# tviibh16m register map
Vendor: Infineon Technologies; Series: TVIIBH16M; File version: 1.0
CPU: CM7 r0p1, little endian, MPU, FPU, double-precision FPU, I-cache, D-cache, VTOR, ITCM, DTCM, 3 interrupt priority bits, 16 interrupts
Registers are 32-bit, read-write, reset 0x0 unless marked. A register's access mark holds for its fields unless they carry their own. Offsets are from the block's base; [hi:lo] are bit positions; {n}, {i} and the like mark numbered series; 'fields as' and 'values as' point back to an identical list.

## FLEXRAY0 (part 2 of 3) — FlexRay Bus Interface
Base 0x40560000
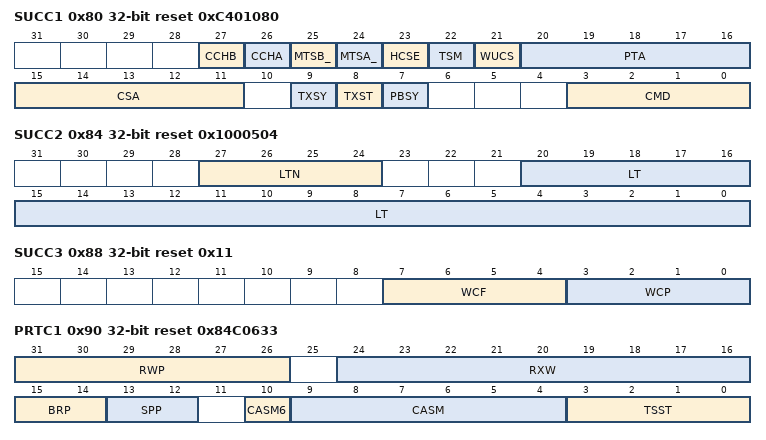
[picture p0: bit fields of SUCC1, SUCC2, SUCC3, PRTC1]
0x80 SUCC1 reset 0xC401080 — SUC Configuration Register 1
  [27] CCHB — Connected to Channel B (pChannels) Configures whether the node is connected to channel B. 1 = Node connected to channel B (default after hard reset) 0 = Not connected to channel B
    0=CH_B_NOT_CONNECTED (N/A); 1=CH_B_CONNECTED (N/A)
  [26] CCHA — Connected to Channel A (pChannels) Configures whether the node is connected to channel A. 1 = Node connected to channel A (default after hard reset) 0 = Not connected to channel A
    0=CH_A_NOT_CONNECTED (N/A); 1=CH_A_CONNECTED (N/A)
  [25] MTSB_ — Select Channel B for MTS Transmission The bit selects channel B for MTS symbol transmission. The flag is reset by default and may be modified only in DEFAULT_CONFIG or CONFIG state. 1 = Channel B selected for MTS transmission 0 = Channel B disabled for MTS transmission
    0=CH_B_DISABLED_FOR_MTS_TXMN (N/A); 1=CH_B_SELECTED_FOR_MTS_TXMN (N/A)
  [24] MTSA_ — Select Channel A for MTS Transmission The bit selects channel A for MTS symbol transmission. The flag is reset by default and may be modified only in DEFAULT_CONFIG or CONFIG state. 1 = Channel A selected for MTS transmission 0 = Channel A disabled for MTS transmission
    0=CH_A_DISABLED_FOR_MTS_TXMN (N/A); 1=CH_A_SELECTED_FOR_MTS_TXMN (N/A)
  [23] HCSE — Halt due to Clock Sync Error (pAllowHaltDueToClock) Controls the transition to HALT state due to a clock synchronization error. The bit can be modified in DEFAULT_CONFIG or CONFIG state only. 1 = CC will enter HALT state 0 = CC will enter / remain in NORMAL_PASSIVE
    0=CC_TO_ENTER_NORMAL_PASSIVE (N/A); 1=CC_TO_ENTER_HALT (N/A)
  [22] TSM — Transmission Slot Mode (pSingleSlotEnabled) Selects the initial transmission slot mode. In SINGLE slot mode the CC may only transmit in the preconfigured key slot. The key slot ID is configured in the header section of message buffer 0 respectively message buffers 0 and 1 depending on bit MRC.SPLM. In case TSM = '1', message buffer 0 respectively message buffers 0,1 can be (re)configured in DEFAULT_CONFIG or CONFIG state only. In ALL slot mode the CC may transmit in all slots. TSM is a configuration bit which can only be set / reset by the Host. The bit can be written in DEFAULT_CONFIG or CONFIG state only. The CC changes to ALL slot mode when the Host successfully applied the ALL_SLOTS command by writing CMD[3:0] = '0101' in POC states NORMAL_ACTIVE or NORMAL_PASSIVE. The actual slot mode is monitored by CCSV.SLM[1:0]. 1 = SINGLE Slot Mode (default after hard reset) 0 = ALL Slot Mode
    0=ALL_SLOT_MODE (N/A); 1=SINGLE_SLOT_MODE (N/A)
  [21] WUCS — Wakeup Channel Select (pWakeupChannel) With this bit the Host selects the channel on which the CC sends the Wakeup pattern. The CC ignores any attempt to change the status of this bit when not in DEFAULT_CONFIG or CONFIG state. 1 = Send wakeup pattern on channel B 0 = Send wakeup pattern on channel A
    0=SEND_WKUP_PATTERN_ON_CH_A (N/A); 1=SEND_WKUP_PATTERN_ON_CH_B (N/A)
  [20:16] PTA — Passive to Active (pAllowPassiveToActive) Defines the number of consecutive even / odd cycle pairs that must have valid clock correction terms before the CC is allowed to transit from NORMAL_PASSIVE to NORMAL_ACTIVE state. If set to '00000' the CC is not allowed to transit from NORMAL_PASSIVE to NORMAL_ACTIVE state. It can be modified in DEFAULT_CONFIG or CONFIG state only. Valid values are 0 to 31 even / odd cycle pairs.
  [15:11] CSA — Cold Start Attempts (gColdStartAttempts) Configures the maximum number of attempts that a cold starting node is permitted to try to start up the network without receiving any valid response from another node. It can be modified in DEFAULT_CONFIG or CONFIG state only. Must be identical in all nodes of a cluster. Valid values are 2 to 31.
    2=MIN (N/A)
  [9] TXSY — Transmit Sync Frame in Key Slot (pKeySlotUsedForSync) Defines whether the key slot is used to transmit sync frames. The bit can be modified in DEFAULT_CONFIG or CONFIG state only. 1 = Key slot used to transmit sync frame, node is sync node 0 = No sync frame transmission in key slot, node is neither sync nor coldstart node
    0=NO_SYNC_FRAME_TXMN (N/A); 1=SYNC_FRAME_TXMN (N/A)
  [8] TXST — Transmit Startup Frame in Key Slot (pKeySlotUsedForStartup) Defines whether the key slot is used to transmit startup frames. The bit can be modified in DEFAULT_CONFIG or CONFIG state only. 1 = Key slot used to transmit startup frame, node is leading or following coldstarter 0 = No startup frame transmission in key slot, node is non-coldstarter
    0=NO_STARTUP_FRAME_TXMN (N/A); 1=STARTUP_FRAME_TXMN (N/A)
  [7] PBSY ro — POC Busy Signals that the POC is busy and cannot accept a command from the Host. CMD[3:0] is locked against write accesses. Set to '1' after hard reset during initialization of internal RAM blocks. 1 = POC is busy, CMD[3:0] locked 0 = POC not busy, CMD[3:0] writeable
    0=POC_NOT_BUSY (N/A); 1=POC_BUSY (N/A)
  [3:0] CMD
    0=CMD_NOT_ACCEPTED (N/A); 1=CONFIG (N/A); 2=READY (N/A); 3=WAKEUP (N/A); 4=RUN (N/A); 5=ALL_SLOTS (N/A); 6=HALT (N/A); 7=FREEZE (N/A); 8=SEND_MTS (N/A); 9=ALLOW_COLDSTART (N/A); 10=RESET_STATUS_INDICATORS (N/A); 11=MONITOR_MODE (N/A); 12=CLEAR_RAMS (N/A)
0x84 SUCC2 reset 0x1000504 — SUC Configuration Register 2
  [27:24] LTN — Listen Timeout Noise (gListenNoise - 1) Configures the upper limit for startup and wakeup listen timeout in the presence of noise expressed as a multiple of pdListenTimeout. The range for gListenNoise is 2 to 16. LTN[3:0] must be configured identical in all nodes of a cluster.
    1=MIN (N/A)
  [20:0] LT — Listen Timeout (pdListenTimeout) Configures wakeup / startup listen timeout in uT. The range for pdListenTimeout is 1284 to 1283846 uT.
0x88 SUCC3 reset 0x11 — SUC Configuration Register 3
  [7:4] WCF — Maximum Without Clock Correction Fatal (gMaxWithoutClockCorrectionFatal) Defines the number of consecutive even / odd cycle pairs with missing clock correction terms that will cause a transition from NORMAL_ACTIVE or NORMAL_PASSIVE to HALT state. Must be identical in all nodes of a cluster. Valid values are 1 to 15 cycle pairs.
    1=MIN (N/A)
  [3:0] WCP — Maximum Without Clock Correction Passive (gMaxWithoutClockCorrectionPassive) Defines the number of consecutive even / odd cycle pairs with missing clock correction terms that will cause a transition from NORMAL_ACTIVE to NORMAL_PASSIVE state. Must be identical in all nodes of a cluster. Valid values are 1 to 15 cycle pairs.
    1=MIN (N/A)
0x8C NEMC — NEM Configuration Register
  [3:0] NML — Network Management Vector Length (gNetworkManagementVectorLength) These bits configure the length of the NM vector. The configured length must be identical in all nodes of a cluster. Valid values are 0 to 12 bytes.
    12=MAX (N/A)
0x90 PRTC1 reset 0x84C0633 — PRT Configuration Register 1
  [31:26] RWP — Repetitions of Tx Wakeup Pattern (pWakeupPattern) Configures the number of repetitions (sequences) of the Tx wakeup symbol. Valid values are 2 to 63.
    2=MIN (N/A)
  [24:16] RXW — Wakeup Symbol Receive Window Length (gdWakeupSymbolRxWindow) Configures the number of bit times used by the node to test the duration of the received wakeup pattern. Must be identical in all nodes of a cluster. Valid values are 76 to 301 bit times.
  [15:14] BRP — Baud Rate Prescaler (gdSampleClockPeriod, pSamplesPerMicrotick) The Baud Rate Prescaler configures the baud rate on the FlexRay bus. The baud rates listed below are valid with a sample clock eray_sclk = 80 MHz. One bit time always consists of 8 samples independent of the configured baud rate. 00 = 10 MBit/s (default) gdSampleClockPeriod = 12.5 ns = 1 - eray_sclk pSamplesPerMicrotick = 2 (1 uT = 25 ns) 01 = 5 MBit/s gdSampleClockPeriod = 25 ns = 2 - eray_sclk pSamplesPerMicrotick = 1 (1 uT = 25 ns) 10, 11 = 2.5 MBit/s gdSampleClockPeriod = 50 ns = 4 - eray_sclk pSamplesPerMicrotick = 1 (1 uT = 50 ns)
    0=BAUD_10_MBPS (N/A); 1=BAUD_5_MBPS (N/A); 2=BAUD_2P5_MBPS (N/A); 3=BAUD_2P5_MBPS_MIRROR (N/A)
  [13:12] SPP — Strobe Point Position Defines the sample count value for strobing. The strobed bit value is set to the voted value when the sample count is incremented to the value configured by SPP[1:0]. 00, 11= Sample 5 (default) 01 = Sample 4 10 = Sample 6
    0=SAMPLE_5 (N/A); 3=SAMPLE_5_MIRROR (N/A); 1=SAMPLE_4 (N/A); 2=SAMPLE_6 (N/A)
  [10] CASM6 ro — Part of CASM[6:0], but fixed to 1
  [9:4] CASM — Collision Avoidance Symbol Max (gdCASRxLowMax) Configures the upper limit of the acceptance window for a collision avoidance symbol (CAS). CASM6 is fixed to '1'. Valid values are 67 to 99 bit times, corresponding to a CASM range (without CASM6) of 3 to 35.
    3=MIN (N/A); 35=MAX (N/A)
  [3:0] TSST — Transmission Start Sequence Transmitter (gdTSSTransmitter) Configures the duration of the Transmission Start Sequence (TSS) in terms of bit times (1 bit time = 4 uT = 100ns@10Mbps). Must be identical in all nodes of a cluster. Valid values are 3 to 15 bit times.
    3=MIN (N/A); 15=MAX (N/A)
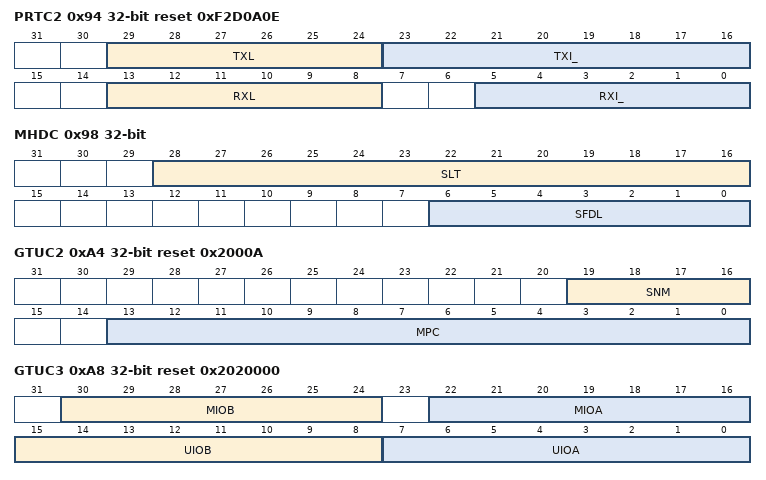
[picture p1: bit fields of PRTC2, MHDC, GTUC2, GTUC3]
0x94 PRTC2 reset 0xF2D0A0E — PRT Configuration Register 2
  [29:24] TXL — Wakeup Symbol Transmit Low (gdWakeupSymbolTxLow) Configures the number of bit times used by the node to transmit the low phase of the wakeup symbol. Must be identical in all nodes of a cluster. Valid values are 15 to 60 bit times.
    15=MIN (N/A); 60=MAX (N/A)
  [23:16] TXI_ — Wakeup Symbol Transmit Idle (gdWakeupSymbolTxIdle) Configures the number of bit times used by the node to transmit the idle phase of the wakeup symbol. Must be identical in all nodes of a cluster. Valid values are 45 to 180 bit times.
  [13:8] RXL — Wakeup Symbol Receive Low (gdWakeupSymbolRxLow) Configures the number of bit times used by the node to test the duration of the low phase of the received wakeup symbol. Must be identical in all nodes of a cluster. Valid values are 10 to 55 bit times.
    10=MIN (N/A); 55=MAX (N/A)
  [5:0] RXI_ — Wakeup Symbol Receive Idle (gdWakeupSymbolRxIdle) Configures the number of bit times used by the node to test the duration of the idle phase of the received wakeup symbol. Must be identical in all nodes of a cluster. Valid values are 14 to 59 bit times.
    14=MIN (N/A); 59=MAX (N/A)
0x98 MHDC — MHD Configuration Register
  [28:16] SLT — Start of Latest Transmit (pLatestTx) Configures the maximum minislot value allowed before inhibiting frame transmission in the dynamic segment of the cycle. There is no transmission in dynamic segment if SLT[12:0] is set to zero. Valid values are 0 to 7981 minislots.
  [6:0] SFDL — Static Frame Data Length (gPayloadLengthStatic) Configures the cluster-wide payload length for all frames sent in the static segment in double bytes. The payload length must be identical in all nodes of a cluster. Valid values are 0 to 127.
0xA0 GTUC1 reset 0x280 — GTU Configuration Register 1
  [19:0] UT — Microtick per Cycle (pMicroPerCycle) Configures the duration of the communication cycle in microticks. Valid values are 640 to 640000 uT.
0xA4 GTUC2 reset 0x2000A — GTU Configuration Register 2
  [19:16] SNM — Sync Node Max (gSyncNodeMax) Maximum number of frames within a cluster with sync frame indicator bit SYN set to '1'. Must be identical in all nodes of a cluster. Valid values are 2 to 15.
    2=MIN (N/A); 15=MAX (N/A)
  [13:0] MPC — Macrotick Per Cycle (gMacroPerCycle) Configures the duration of one communication cycle in macroticks. The cycle length must be identical in all nodes of a cluster. Valid values are 10 to 16000 MT.
0xA8 GTUC3 reset 0x2020000 — GTU Configuration Register 3
  [30:24] MIOB — Macrotick Initial Offset Channel B (pMacroInitialOffset[B]) Configures the number of macroticks between the static slot boundary and the subsequent macrotick boundary of the secondary time reference point based on the nominal macrotick duration. Must be identical in all nodes of a cluster. Valid values are 2 to 72 MT.
  [22:16] MIOA — Macrotick Initial Offset Channel A (pMacroInitialOffset[A]) Configures the number of macroticks between the static slot boundary and the subsequent macrotick boundary of the secondary time reference point based on the nominal macrotick duration. Must be identical in all nodes of a cluster. Valid values are 2 to 72 MT.
  [15:8] UIOB — Microtick Initial Offset Channel B (pMicroInitialOffset[B]) Configures the number of microticks between the actual time reference point on channel B and the subsequent macrotick boundary of the secondary time reference point. The parameter depends on pDelayCompensation[B] and therefore has to be set for each channel independently. Valid values are 0 to 240 uT.
  [7:0] UIOA — Microtick Initial Offset Channel A (pMicroInitialOffset[A]) Configures the number of microticks between the actual time reference point on channel A and the subsequent macrotick boundary of the secondary time reference point. The parameter depends on pDelayCompensation[A] and therefore has to be set for each channel independently. Valid values are 0 to 240 uT.
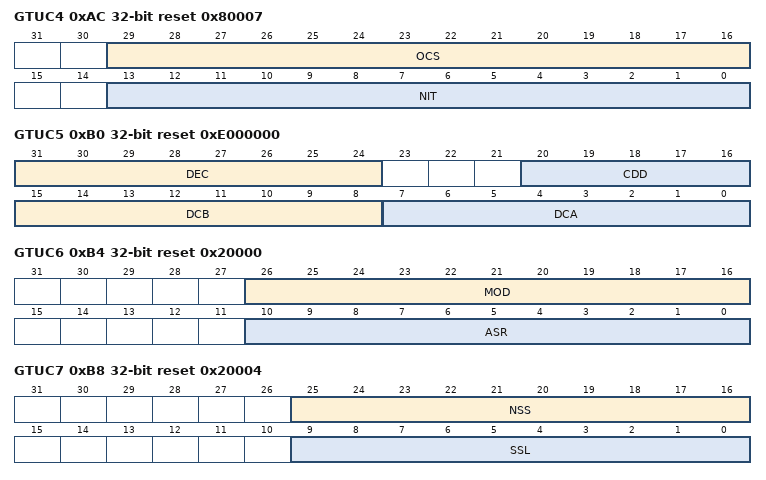
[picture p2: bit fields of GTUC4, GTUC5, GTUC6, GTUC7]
0xAC GTUC4 reset 0x80007 — GTU Configuration Register 4
  [29:16] OCS — Offset Correction Start (gOffsetCorrectionStart - 1) Determines the start of the offset correction within the NIT phase, calculated from start of cycle. Must be identical in all nodes of a cluster. For cluster consisting of E-Ray implementations only, it is sufficient to program OCS = NIT + 1. Valid values are 8 to 15998 MT.
  [13:0] NIT — Network Idle Time Start (gMacroPerCycle - gdNIT - 1) Configures the starting point of the Network Idle Time NIT at the end of the communication cycle expressed in terms of macroticks from the beginning of the cycle. The start of NIT is recognized if Macrotick = gMacroPerCycle - gdNIT -1 and the increment pulse of Macrotick is set. Must be identical in all nodes of a cluster. Valid values are 7 to 15997 MT.
0xB0 GTUC5 reset 0xE000000 — GTU Configuration Register 5
  [31:24] DEC — Decoding Correction (pDecodingCorrection) Configures the decoding correction value used to determine the primary time reference point. Valid values are 14 to 143 uT.
  [20:16] CDD — Cluster Drift Damping (pClusterDriftDamping) Configures the cluster drift damping value used in clock synchronization to minimize accumulation of rounding errors. Valid values are 0 to 20 uT.
    20=MAX (N/A)
  [15:8] DCB — Delay Compensation Channel B (pDelayCompensation[B]) Used to compensate for reception delays on the indicated channel. This covers assumed propagation delay up to cPropagationDelayMax for microticks in the range of 0.0125 to 0.05us. In practice, the minimum of the propagation delays of all sync nodes should be applied. Valid values are 0 to 200 uT.
  [7:0] DCA — Delay Compensation Channel A (pDelayCompensation[A]) Used to compensate for reception delays on the indicated channel. This covers assumed propagation delay up to cPropagationDelayMax for microticks in the range of 0.0125 to 0.05us. In practice, the minimum of the propagation delays of all sync nodes should be applied. Valid values are 0 to 200 uT.
0xB4 GTUC6 reset 0x20000 — GTU Configuration Register 6
  [26:16] MOD — Maximum Oscillator Drift (pdMaxDrift) Maximum drift offset between two nodes that operate with unsynchronized clocks over one communication cycle in uT. Valid values are 2 to 1923 uT.
  [10:0] ASR — Accepted Startup Range (pdAcceptedStartupRange) Number of microticks constituting the expanded range of measured deviation for startup frames during integration. Valid values are 0 to 1875 uT.
0xB8 GTUC7 reset 0x20004 — GTU Configuration Register 7
  [25:16] NSS — Number of Static Slots (gNumberOfStaticSlots) Configures the number of static slots in a cycle. At least 2 coldstart nodes must be configured to startup a FlexRay network. The number of static slots must be identical in all nodes of a cluster. Valid values are 2 to 1023.
  [9:0] SSL — Static Slot Length (gdStaticSlot) Configures the duration of a static slot in macroticks. The static slot length must be identical in all nodes of a cluster. Valid values are 4 to 659 MT.
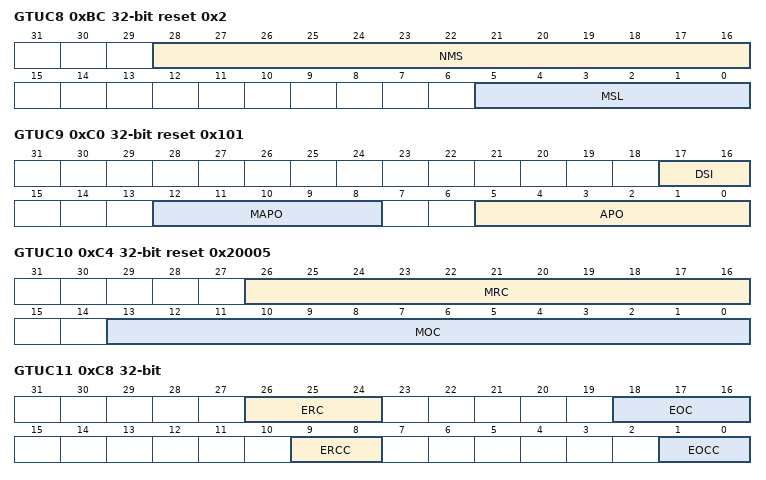
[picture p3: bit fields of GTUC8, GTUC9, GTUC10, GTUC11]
0xBC GTUC8 reset 0x2 — GTU Configuration Register 8
  [28:16] NMS — Number of Minislots (gNumberOfMinislots) Configures the number of minislots within the dynamic segment of a cycle. The number of minislots must be identical in all nodes of a cluster. Valid values are 0 to 7986.
  [5:0] MSL — Minislot Length (gdMinislot) Configures the duration of a minislot in macroticks. The minislot length must be identical in all nodes of a cluster. Valid values are 2 to 63 MT.
    2=MIN (N/A); 63=MAX (N/A)
0xC0 GTUC9 reset 0x101 — GTU Configuration Register 9
  [17:16] DSI — Dynamic Slot Idle Phase (gdDynamicSlotIdlePhase) The duration of the dynamic slot idle phase has to be greater or equal than the idle detection time. Must be identical in all nodes of a cluster. Valid values are 0 to 2 Minislot.
    2=MAX (N/A)
  [12:8] MAPO — Minislot Action Point Offset (gdMinislotActionPointOffset) Configures the action point offset in macroticks within the minislots of the dynamic segment. Must be identical in all nodes of a cluster. Valid values are 1 to 31 MT.
    1=MIN (N/A)
  [5:0] APO — Action Point Offset (gdActionPointOffset) Configures the action point offset in macroticks within static slots and symbol window. Must be identical in all nodes of a cluster. Valid values are 1 to 63 MT.
    1=MIN (N/A)
0xC4 GTUC10 reset 0x20005 — GTU Configuration Register 10
  [26:16] MRC — Maximum Rate Correction (pRateCorrectionOut) Holds the maximum permitted rate correction value to be applied by the internal clock synchronization algorithm. The CC checks only the internal rate correction value against the maximum rate correction value (absolute value). Valid values are 2 to 1923 uT.
  [13:0] MOC — Maximum Offset Correction (pOffsetCorrectionOut) Holds the maximum permitted offset correction value to be applied by the internal clock synchronization algorithm (absolute value). The CC checks only the internal offset correction value against the maximum offset correction value. Valid values are 5 to 15266 uT.
0xC8 GTUC11 — GTU Configuration Register 11
  [26:24] ERC — External Rate Correction (pExternRateCorrection) Holds the external rate correction value in microticks to be applied by the internal clock synchronization algorithm. The value is subtracted / added from / to the calculated rate correction value. The value is applied during NIT. May be modified in DEFAULT_CONFIG or CONFIG state only. Valid values are 0 to 7 uT.
  [18:16] EOC — External Offset Correction (pExternOffsetCorrection) Holds the external offset correction value in microticks to be applied by the internal clock synchronization algorithm. The value is subtracted / added from / to the calculated offset correction value. The value is applied during NIT. May be modified in DEFAULT_CONFIG or CONFIG state only. Valid values are 0 to 7 uT.
  [9:8] ERCC — External Rate Correction Control (vExternRateControl) By writing to ERCC[1:0] the external rate correction is enabled as specified below. Should be modified only outside NIT. 00, 01 = No external rate correction 10 = External rate correction value subtracted from calculated rate correction value 11 = External rate correction value added to calculated rate correction value
    0=NO_EXT_RATE_CORRECTION (N/A); 1=NO_EXT_RATE_CORRECTION_MIRROR (N/A); 2=EXT_RATE_CORRECTION_SUBTRACTED (N/A); 3=EXT_RATE_CORRECTION_ADDED (N/A)
  [1:0] EOCC — External Offset Correction Control (vExternOffsetControl) By writing to EOCC[1:0] the external offset correction is enabled as specified below. Should be modified only outside NIT. 00, 01 = No external offset correction 10 = External offset correction value subtracted from calculated offset correction value 11 = External offset correction value added to calculated offset correction value
    0=NO_EXT_OFFSET_CORRECTION (N/A); 1=NO_EXT_OFFSET_CORRECTION_MIRROR (N/A); 2=EXT_OFFSET_CORRECTION_SUBTRACTED (N/A); 3=EXT_OFFSET_CORRECTION_ADDED (N/A)
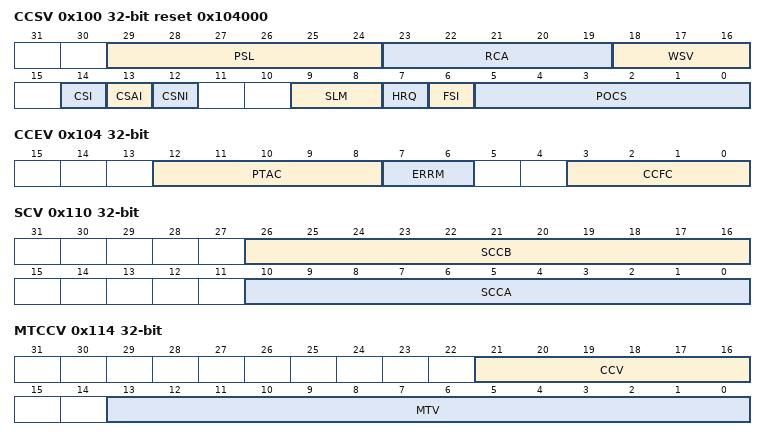
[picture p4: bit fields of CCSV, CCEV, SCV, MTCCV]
0x100 CCSV ro reset 0x104000 — CC Status Vector
  [29:24] PSL — POC Status Log Status of POCS[5:0] immediately before entering HALT state. Set when entering HALT state. Set to HALT when FREEZE command is applied during HALT state and FSI is not already set i.e. the HALT state was not reached by FREEZE command. Reset to '00 0000' when leaving HALT state.
  [23:19] RCA — Remaining Coldstart Attempts (vRemainingColdstartAttempts) Indicates the number of remaining coldstart attempts. The RUN command resets this counter to the maximum number of coldstart attempts as configured by SUCC1.CSA[4:0]. The initial value of RCA[4:0] during CONFIG and DEFAULT_CONFIG state is also SUCC1.CSA[4:0].
  [18:16] WSV
    0=UNDEFINED (N/A); 1=RECEIVED_HEADER (N/A); 2=RECEIVED_WUP (N/A); 3=COLLISION_HEADER (N/A); 4=COLLISION_WUP (N/A); 5=COLLISION_UNKNOWN (N/A); 6=TRANSMITTED (N/A)
  [14] CSI — Cold Start Inhibit (vColdStartInhibit) Indicates that the node is disabled from cold starting. The flag is set whenever the POC enters READY state due to CHI command READY. The flag has to be reset under control of the Host by CHI command ALLOW_COLDSTART (SUCC1.CMD[3:0] = '1001'). 1 = Cold starting of node disabled 0 = Cold starting of node enabled
    0=NODE_COLD_START_ENABLED (N/A); 1=NODE_COLD_START_DISABLED (N/A)
  [13] CSAI — Coldstart Abort Indicator Coldstart aborted. Reset by CHI command RESET_STATUS_INDICATORS or by transition from HALT to DEFAULT_CONFIG state or from READY to STARTUP state.
  [12] CSNI — Coldstart Noise Indicator (vPOC!ColdstartNoise) Indicates that the cold start procedure occurred under noisy conditions. Reset by CHI command RESET_STATUS_INDICATORS or by transition from HALT to DEFAULT_CONFIG state or from READY to STARTUP state.
  [9:8] SLM
    0=SINGLE (N/A); 2=ALL_PENDING (N/A); 3=ALL (N/A)
  [7] HRQ — Halt Request (vPOC!CHIHaltRequest) Indicates that a request from the Host has been received to halt the POC at the end of the communication cycle. Reset by transition from HALT to DEFAULT_CONFIG state or when entering READY state.
  [6] FSI — Freeze Status Indicator (vPOC!Freeze) Indicates that the POC has entered the HALT state due to CHI command FREEZE or due to an error condition requiring an immediate POC halt. Reset by transition from HALT to DEFAULT_CONFIG state.
  [5:0] POCS
    0=DEFAULT_CONFIG (N/A); 1=READY (N/A); 2=NORMAL_ACTIVE (N/A); 3=NORMAL_PASSIVE (N/A); 4=HALT (N/A); 5=MONITOR_MODE (N/A); 15=CONFIG (N/A); 16=WAKEUP_STANDBY (N/A); 17=WAKEUP_LISTEN (N/A); 18=WAKEUP_SEND (N/A); 19=WAKEUP_DETECT (N/A); 32=STARTUP_PREPARE (N/A); 33=COLDSTART_LISTEN (N/A); 34=COLDSTART_COLLISION_RESOLUTION (N/A); 35=COLDSTART_CONSISTENCY_CHECK (N/A); 36=COLDSTART_GAP (N/A); 37=COLDSTART_JOIN (N/A); 38=INTEGRATION_COLDSTART_CHECK (N/A); 39=INTEGRATION_LISTEN (N/A); 40=INTEGRATION_CONSISTENCY_CHECK (N/A); 41=INITIALIZE_SCHEDULE (N/A); 42=ABORT_STARTUP (N/A); 43=STARTUP_SUCCESS (N/A)
0x104 CCEV ro — CC Error Vector
  [12:8] PTAC — Passive to Active Count (vAllowPassiveToActive) Indicates the number of consecutive even / odd cycle pairs that have passed with valid rate and offset correction terms, while the node is waiting to transit from NORMAL_PASSIVE state to NORMAL_ACTIVE state. The transition takes place when PTAC[4:0] equals SUCC1.PTA[4:0] -1.
  [7:6] ERRM
    0=ACTIVE (N/A); 1=PASSIVE (N/A); 2=COMM_HALT (N/A)
  [3:0] CCFC — Clock Correction Failed Counter (vClockCorrectionFailed) The Clock Correction Failed Counter is incremented by one at the end of any odd communication cycle where either the missing offset correction error or missing rate correction error are active. The Clock Correction Failed Counter is reset to '0' at the end of an odd communication cycle if neither the offset correction failed nor the rate correction failed errors are active. The Clock Correction Failed Counter stops at 15.
0x110 SCV ro — Slot Counter Value
  [26:16] SCCB — Slot Counter Channel B (vSlotCounter[B]) Current slot counter value on channel B. The value is incremented by the CC and reset at the start of a communication cycle. Valid values are 0 to 2047.
  [10:0] SCCA — Slot Counter Channel A (vSlotCounter[A]) Current slot counter value on channel A. The value is incremented by the CC and reset at the start of a communication cycle. Valid values are 0 to 2047.
0x114 MTCCV ro — Macrotick and Cycle Counter Value
  [21:16] CCV — Cycle Counter Value (vCycleCounter) Current cycle counter value. The value is incremented by the CC at the start of a communication cycle. Valid values are 0 to 63.
  [13:0] MTV — Macrotick Value (vMacrotick) Current macrotick value. The value is incremented by the CC and reset at the start of a communication cycle. Valid values are 0 to 15999.
0x118 RCV ro — Rate Correction Value
  [11:0] RCV — Rate Correction Value (vRateCorrection) Rate correction value (two's complement). Calculated internal rate correction value before limitation. If the RCV value exceeds the limits defined by GTUC10.MRC[10:0], flag SFS.RCLR is set to '1'.
0x11C OCV ro — Offset Correction Value
  [18:0] OCV — Offset Correction Value (vOffsetCorrection) Offset correction value (two's complement). Calculated internal offset correction value before limitation. If the OCV value exceeds the limits defined by GTUC10.MOC[13:0], flag SFS.OCLR is set to '1'.
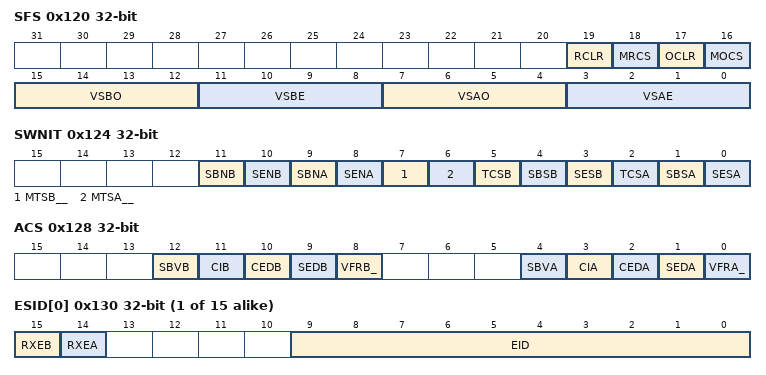
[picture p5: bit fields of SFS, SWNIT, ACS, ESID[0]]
0x120 SFS ro — Sync Frame Status
  [19] RCLR — Rate Correction Limit Reached The Rate Correction Limit Reached flag signals to the Host, that the rate correction value has exceeded its limit as defined by GTUC10.MRC[10:0]. The flag is updated by the CC at start of offset correction phase. 1 = Rate correction limit reached 0 = Rate correction below limit
    0=RATE_CORRECTION_BELOW_LIMIT (N/A); 1=RATE_CORRECTION_LIMIT_REACHED (N/A)
  [18] MRCS — Missing Rate Correction Signal The Missing Rate Correction flag signals to the Host, that no rate correction calculation can be performed because no pairs of even / odd sync frames were received. The flag is updated by the CC at start of offset correction phase. 1 = Missing rate correction signal 0 = Rate correction signal valid
    0=RATE_CORRECTION_SIGNAL_VALID (N/A); 1=RATE_CORRECTION_SIGNAL_INVALID (N/A)
  [17] OCLR — Offset Correction Limit Reached The Offset Correction Limit Reached flag signals to the Host, that the offset correction value has exceeded its limit as defined by GTUC10.MOC[13:0]. The flag is updated by the CC at start of offset correction phase. 1 = Offset correction limit reached 0 = Offset correction below limit
    0=OFFSET_CORRECTION_BELOW_LIMIT (N/A); 1=OFFSET_CORRECTION_LIMIT_REACHED (N/A)
  [16] MOCS — Missing Offset Correction Signal The Missing Offset Correction flag signals to the Host, that no offset correction calculation can be performed because no sync frames were received. The flag is updated by the CC at start of offset correction phase. 1 = Missing offset correction signal 0 = Offset correction signal valid
    0=OFFSET_CORRECTION_SIGNAL_VALID (N/A); 1=OFFSET_CORRECTION_SIGNAL_INVALID (N/A)
  [15:12] VSBO — Valid Sync Frames Channel B, odd communication cycle Holds the number of valid sync frames received on channel B in the odd communication cycle. If transmission of sync frames is enabled by SUCC1.TXSY the value is incremented by one. The value is updated during the NIT of each odd communication cycle.
  [11:8] VSBE — Valid Sync Frames Channel B, even communication cycle Holds the number of valid sync frames received on channel B in the even communication cycle. If transmission of sync frames is enabled by SUCC1.TXSY the value is incremented by one. The value is updated during the NIT of each even communication cycle.
  [7:4] VSAO — Valid Sync Frames Channel A, odd communication cycle Holds the number of valid sync frames received on channel A in the odd communication cycle. If transmission of sync frames is enabled by SUCC1.TXSY the value is incremented by one. The value is updated during the NIT of each odd communication cycle.
  [3:0] VSAE — Valid Sync Frames Channel A, even communication cycle Holds the number of valid sync frames received on channel A in the even communication cycle. If transmission of sync frames is enabled by SUCC1.TXSY the value is incremented by one. The value is updated during the NIT of each even communication cycle.
0x124 SWNIT ro — Symbol Window and NIT Status
  [11] SBNB — Slot Boundary Violation during NIT Channel B (vSS!BViolationB) 1 = Slot boundary violation during NIT detected on channel B 0 = No slot boundary violation detected
    0=NO_BNDRY_VIOLATION_ERROR_IN_CH_B (N/A); 1=BNDRY_VIOLATION_ERROR_IN_CH_B (N/A)
  [10] SENB — Syntax Error during NIT Channel B (vSS!SyntaxErrorB) 1 = Syntax error during NIT detected on channel B 0 = No syntax error detected
    0=NO_SYNTAX_ERROR_DETECTED_ON_CH_B (N/A); 1=SYNTAX_ERROR_DETECTED_ON_CH_B (N/A)
  [9] SBNA — Slot Boundary Violation during NIT Channel A (vSS!BViolationA) 1 = Slot boundary violation during NIT detected on channel A 0 = No slot boundary violation detected
    0=NO_BNDRY_VIOLATION_ERROR_IN_CH_A (N/A); 1=BNDRY_VIOLATION_ERROR_IN_CH_A (N/A)
  [8] SENA — Syntax Error during NIT Channel A (vSS!SyntaxErrorA) 1 = Syntax error during NIT detected on channel A 0 = No syntax error detected
    0=NO_SYNTAX_ERROR_DETECTED_ON_CH_A (N/A); 1=SYNTAX_ERROR_DETECTED_ON_CH_A (N/A)
  [7] MTSB__ — MTS Received on Channel B (vSS!ValidMTSB) Media Access Test symbol received on channel B during the preceding symbol window. Updated by the CC for each channel at the end of the symbol window. When this bit is set to '1', also interrupt flag SIR.MTSB is set to '1'. 1 = MTS symbol received on channel B 0 = No MTS symbol received on channel B NIT related status information. Updated by the CC at the end of the NIT for each channel:
    0=NO_MTS_SYMBOL_RXD_IN_CH_B (N/A); 1=MTS_SYMBOL_RXD_IN_CH_B (N/A)
  [6] MTSA__ — MTS Received on Channel A (vSS!ValidMTSA) Media Access Test symbol received on channel A during the preceding symbol window. Updated by the CC for each channel at the end of the symbol window. When this bit is set to '1', also interrupt flag SIR.MTSA is set to '1'. 1 = MTS symbol received on channel A 0 = No MTS symbol received on channel A
    0=NO_MTS_SYMBOL_RXD_IN_CH_A (N/A); 1=MTS_SYMBOL_RXD_IN_CH_A (N/A)
  [5] TCSB — Transmission Conflict in Symbol Window Channel B (vSS!TxConflictB) 1 = Transmission conflict in symbol window detected on channel B 0 = No transmission conflict detected
    0=NO_TXMN_CONFLICT_IN_CH_B (N/A); 1=TXMN_CONFLICT_IN_CH_B (N/A)
  [4] SBSB — Slot Boundary Violation in Symbol Window Channel B (vSS!BViolationB) 1 = Slot boundary violation during symbol window detected on channel B 0 = No slot boundary violation detected
    values as SBNB
  [3] SESB — Syntax Error in Symbol Window Channel B (vSS!SyntaxErrorB) 1 = Syntax error during symbol window detected on channel B 0 = No syntax error detected
    0=NO_SYNTAX_ERROR_IN_CH_B (N/A); 1=SYNTAX_ERR_IN_CH_B (N/A)
  [2] TCSA — Transmission Conflict in Symbol Window Channel A (vSS!TxConflictA) 1 = Transmission conflict in symbol window detected on channel A 0 = No transmission conflict detected
    0=NO_TXMN_CONFLICT_IN_CH_A (N/A); 1=TXMN_CONFLICT_IN_CH_A (N/A)
  [1] SBSA — Slot Boundary Violation in Symbol Window Channel A (vSS!BViolationA) 1 = Slot boundary violation during symbol window detected on channel A 0 = No slot boundary violation detected
    values as SBNA
  [0] SESA — Syntax Error in Symbol Window Channel A (vSS!SyntaxErrorA) 1 = Syntax error during symbol window detected on channel A 0 = No syntax error detected
    0=NO_SYNTAX_ERROR_IN_CH_A (N/A); 1=SYNTAX_ERR_IN_CH_A (N/A)
0x128 ACS — Aggregated Channel Status
  [12] SBVB write-1-clears — Slot Boundary Violation on Channel B (vSS!BViolationB) One or more slot boundary violations were observed on channel B at any time during the observation period (static or dynamic slots, symbol window, and NIT). 1 = Slot boundary violation(s) observed on channel B 0 = No slot boundary violation observed
    values as SWNIT.SBNB
  [11] CIB write-1-clears — Communication Indicator Channel B One or more valid frames were received on channel B in slots that also contained any additional communication during the observation period, i.e. one or more slots received a valid frame AND had any combination of either syntax error OR content error OR slot boundary violation. 1 = Valid frame(s) received on channel B in slots containing any additional communication 0 = No valid frame(s) received in slots containing any additional communication
    0=NO_VALID_FRAME_RXD_ON_CH_B_IN_SLOTS (N/A); 1=VALID_FRAME_RXD_ON_CH_B_IN_SLOTS (N/A)
  [10] CEDB write-1-clears — Content Error Detected on Channel B (vSS!ContentErrorB) One or more frames with a content error were received on channel B in any static or dynamic slot during the observation period. 1 = Frame(s) with content error received on channel B 0 = No frame with content error received
    0=NO_FRAME_WITH_CONTENT_ERR_ON_CH_B (N/A); 1=FRAME_WITH_CONTENT_ERR_RXD_ON_CH_B (N/A)
  [9] SEDB write-1-clears — Syntax Error Detected on Channel B (vSS!SyntaxErrorB) One or more syntax errors in static or dynamic slots, symbol window, and NIT were observed on channel B. 1 = Syntax error(s) observed on channel B 0 = No syntax error observed
    0=NO_SYNTAX_ERR_OBSVD_ON_CH_B (N/A); 1=SYNTAX_ERR_OBSVD_ON_CH_B (N/A)
  [8] VFRB_ write-1-clears — Valid Frame Received on Channel B (vSS!ValidFrameB) One or more valid frames were received on channel B in any static or dynamic slot during the observation period. Reset under control of the Host. 1 = Valid frame(s) received on channel B 0 = No valid frame received
    0=NO_VALID_FRAME_RXD_ON_CH_B (N/A); 1=VALID_FRAME_RXD_ON_CH_B (N/A)
  [4] SBVA write-1-clears — Slot Boundary Violation on Channel A (vSS!BViolationA) One or more slot boundary violations were observed on channel A at any time during the observation period (static or dynamic slots, symbol window, and NIT). 1 = Slot boundary violation(s) observed on channel A 0 = No slot boundary violation observed
    values as SWNIT.SBNA
  [3] CIA write-1-clears — Communication Indicator Channel A One or more valid frames were received on channel A in slots that also contained any additional communication during the observation period, i.e. one or more slots received a valid frame AND had any combination of either syntax error OR content error OR slot boundary violation. 1 = Valid frame(s) received on channel A in slots containing any additional communication 0 = No valid frame(s) received in slots containing any additional communication
    0=NO_VALID_FRAME_RXD_ON_CH_A_IN_SLOTS (N/A); 1=VALID_FRAME_RXD_ON_CH_A_IN_SLOTS (N/A)
  [2] CEDA write-1-clears — Content Error Detected on Channel A (vSS!ContentErrorA) One or more frames with a content error were received on channel A in any static or dynamic slot during the observation period. 1 = Frame(s) with content error received on channel A 0 = No frame with content error received
    0=NO_FRAME_WITH_CONTENT_ERR_ON_CH_A (N/A); 1=FRAME_WITH_CONTENT_ERR_RXD_ON_CH_A (N/A)
  [1] SEDA write-1-clears — Syntax Error Detected on Channel A (vSS!SyntaxErrorA) One or more syntax errors in static or dynamic slots, symbol window, and NIT were observed on channel A. 1 = Syntax error(s) observed on channel A 0 = No syntax error observed
    0=NO_SYNTAX_ERR_OBSVD_ON_CH_A (N/A); 1=SYNTAX_ERR_OBSVD_ON_CH_A (N/A)
  [0] VFRA_ write-1-clears — Valid Frame Received on Channel A (vSS!ValidFrameA) One or more valid frames were received on channel A in any static or dynamic slot during the observation period. 1 = Valid frame(s) received on channel A 0 = No valid frame received
    0=NO_VALID_FRAME_RXD_ON_CH_A (N/A); 1=VALID_FRAME_RXD_ON_CH_A (N/A)
{0x130+4i} ESID[{i}] (i=0..14) ro — Even Sync ID [1...15]
  [15] RXEB — Received / Configured Even Sync ID on Channel B Signals that a sync frame corresponding to the stored even sync ID was received on channel B or that the node is configured to be a sync node with key slot = EID[9:0] (ESID1 only). 1 = Sync frame received on channel B / node configured to transmit sync frames 0 = No sync frame received on channel B / node not configured to transmit sync frames
    0=NO_SYNC_FRAME_RXD_ON_CH_B (N/A); 1=SYNC_FRAME_RXD_ON_CH_B (N/A)
  [14] RXEA — Received / Configured Even Sync ID on Channel A Signals that a sync frame corresponding to the stored even sync ID was received on channel A or that the node is configured to be a sync node with key slot = EID[9:0] (ESID1 only). 1 = Sync frame received on channel A / node configured to transmit sync frames 0 = No sync frame received on channel A / node not configured to transmit sync frames
    0=NO_SYNC_FRAME_RXD_ON_CH_A (N/A); 1=SYNC_FRAME_RXD_ON_CH_A (N/A)
  [9:0] EID — Even Sync ID (vsSyncIDListA,B even) Sync frame ID even communication cycle.
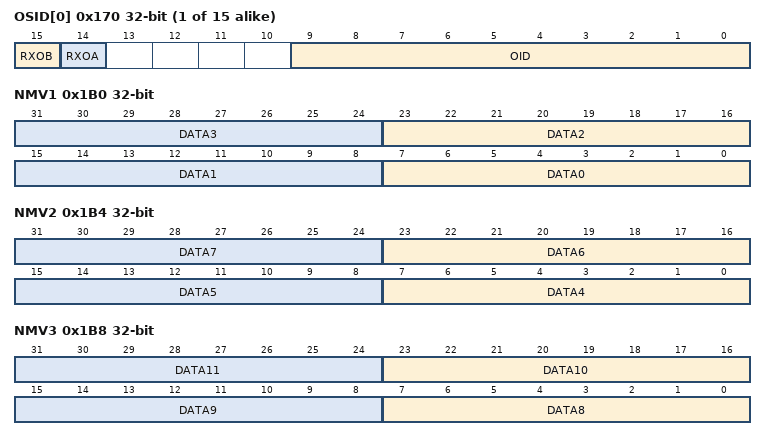
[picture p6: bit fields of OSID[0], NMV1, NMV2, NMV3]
{0x170+4i} OSID[{i}] (i=0..14) ro — Odd Sync ID [1...15]
  [15] RXOB — Received / Configured Odd Sync ID on Channel B Signals that a sync frame corresponding to the stored odd sync ID was received on channel B or that the node is configured to be a sync node with key slot = OID[9:0] (OSID1 only). 1 = Sync frame received on channel B / node configured to transmit sync frames 0 = No sync frame received on channel B / node not configured to transmit sync frames
    values as ESID[0].RXEB
  [14] RXOA — Received / Configured Odd Sync ID on Channel A Signals that a sync frame corresponding to the stored odd sync ID was received on channel A or that the node is configured to be a sync node with key slot = OID[9:0] (OSID1 only). 1 = Sync frame received on channel A / node configured to transmit sync frames 0 = No sync frame received on channel A / node not configured to transmit sync frames
    values as ESID[0].RXEA
  [9:0] OID — Odd Sync ID (vsSyncIDListA,B odd) Sync frame ID odd communication cycle.
0x1B0 NMV1 ro — Network Management Vector 1
  [8n+7:8n] DATA{n} (n=0..3)
0x1B4 NMV2 ro — Network Management Vector 2
  [8n-25:8n-32] DATA{n} (n=4..7)
0x1B8 NMV3 ro — Network Management Vector 3
  [8n-57:8n-64] DATA{n} (n=8..11)
